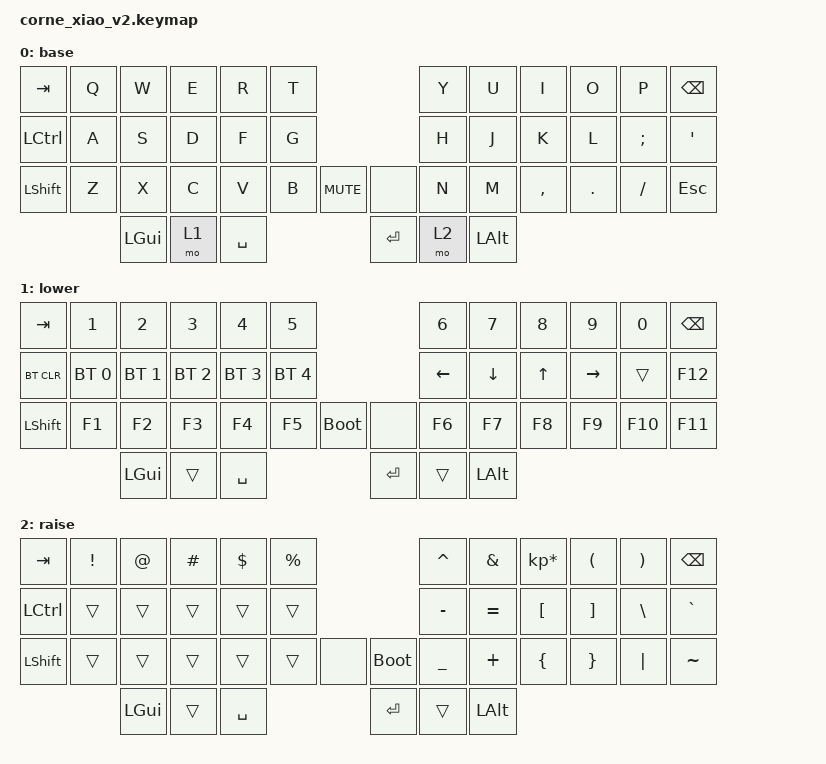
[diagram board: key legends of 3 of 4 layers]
#include <behaviors.dtsi>
#include <dt-bindings/zmk/keys.h>
#include <dt-bindings/zmk/bt.h>
#include <dt-bindings/zmk/pointing.h>

/ {
    combos {
        compatible = "zmk,combos";

        combo_studio_unlock {
            timeout-ms    = <50>;
            key-positions = <0 1>;
            bindings      = <&studio_unlock>;
            layers        = <0>;
        };

        combo_mouse_layer {
            timeout-ms    = <50>;
            key-positions = <1 2>;    /* Q + W on Base */
            bindings      = <&mo 3>;  /* momentary MouseNav (layer 3) */
            layers        = <0>;
        };
    };

    keymap {
        compatible = "zmk,keymap";

        default_layer {
            display-name    = "base";
            sensor-bindings = <&inc_dec_kp C_VOL_UP C_VOL_DN &inc_dec_kp PG_UP PG_DN>;
            bindings = <
&kp TAB   &kp Q   &kp W   &kp E    &kp R   &kp T                      &kp Y   &kp U   &kp I     &kp O   &kp P    &kp BSPC
&kp LCTRL &kp A   &kp S   &kp D    &kp F   &kp G                      &kp H   &kp J   &kp K     &kp L   &kp SEMI &kp SQT
&kp LSHFT &kp Z   &kp X   &kp C    &kp V   &kp B     &kp C_MUTE &none &kp N   &kp M   &kp COMMA &kp DOT &kp FSLH &kp ESC
                      &kp LGUI &mo 1  &kp SPACE                  &kp RET &mo 2  &kp LALT
            >;
        };

        lower_layer {
            display-name    = "lower";
            sensor-bindings = <&inc_dec_kp C_VOL_UP C_VOL_DN &inc_dec_kp PG_UP PG_DN>;
            bindings = <
&kp TAB    &kp N1       &kp N2       &kp N3       &kp N4       &kp N5                        &kp N6   &kp N7   &kp N8   &kp N9    &kp N0   &kp BSPC
&bt BT_CLR &bt BT_SEL 0 &bt BT_SEL 1 &bt BT_SEL 2 &bt BT_SEL 3 &bt BT_SEL 4                  &kp LEFT &kp DOWN &kp UP   &kp RIGHT &trans  &kp F12
&kp LSHFT  &kp F1       &kp F2       &kp F3       &kp F4       &kp F5       &bootloader &none &kp F6   &kp F7   &kp F8   &kp F9    &kp F10 &kp F11
                                     &kp LGUI    &trans       &kp SPACE                     &kp RET  &trans   &kp LALT
            >;
        };

        raise_layer {
            display-name    = "raise";
            sensor-bindings = <&inc_dec_kp C_VOL_UP C_VOL_DN &inc_dec_kp PG_UP PG_DN>;
            bindings = <
&kp TAB   &kp EXCL &kp AT    &kp HASH &kp DLLR &kp PRCNT                  &kp CARET &kp AMPS  &kp KP_MULTIPLY &kp LPAR &kp RPAR &kp BSPC
&kp LCTRL &trans   &trans   &trans   &trans   &trans                     &kp MINUS &kp EQUAL &kp LBKT        &kp RBKT &kp BSLH &kp GRAVE
&kp LSHFT &trans   &trans   &trans   &trans   &trans   &none &bootloader &kp UNDER &kp PLUS  &kp LBRC        &kp RBRC &kp PIPE &kp TILDE
                          &kp LGUI &trans   &kp SPACE                   &kp RET   &trans    &kp LALT
            >;
        };

        MouseNav {
            display-name = "mouse";
            bindings = <
                /* Row 1: placeholder */
                &trans &trans &trans &trans &trans &trans
                &trans &trans &trans &trans &trans &tog 0

                /* Row 2: movement */
                &trans &trans &trans &trans &trans &trans
                &mmv MOVE_LEFT &mmv MOVE_DOWN &mmv MOVE_UP &mmv MOVE_RIGHT &trans &trans

                /* Row 3: scroll up/down fixed */
                &trans &trans &trans &trans &trans &trans
                /* N = scroll up, M = scroll down */
                &msc SCRL_UP &msc SCRL_DOWN &trans &trans &trans &trans

                /* Thumbs: click */
                &trans &trans &trans &mkp MB1 &mkp MB2 &trans &trans
            >;
        };

        extra1 { status = "reserved"; };
        extra2 { status = "reserved"; };
    };
};
